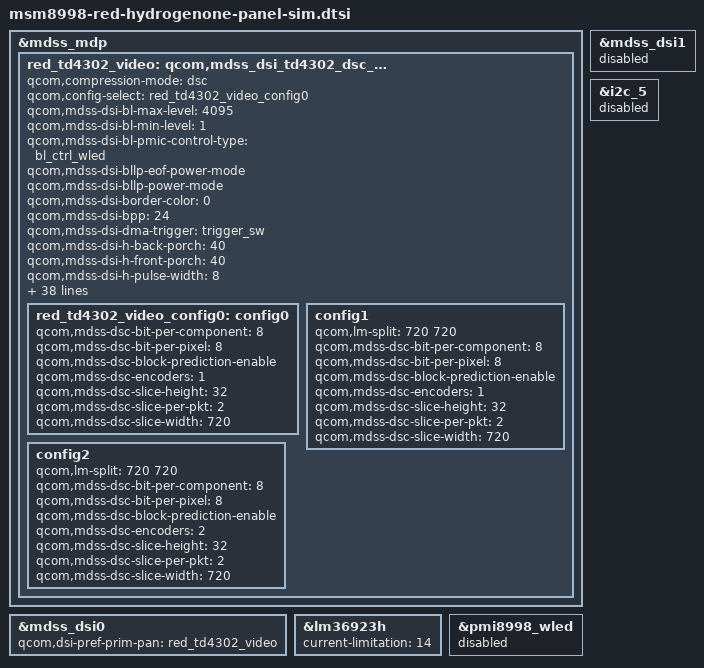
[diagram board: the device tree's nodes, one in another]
/*
 * Copyright (c) 2026, The LineageOS Project. All rights reserved.
 *
 * This program is free software; you can redistribute it and/or modify
 * it under the terms of the GNU General Public License version 2 and
 * only version 2 as published by the Free Software Foundation.
 */

/* SIM display and touch properties are isolated in this layer. */

&mdss_mdp {
	red_td4302_video: qcom,mdss_dsi_td4302_dsc_wqhd_video {
		qcom,compression-mode = "dsc";
		qcom,config-select = <&red_td4302_video_config0>;
		qcom,mdss-dsi-bl-max-level = <4095>;
		qcom,mdss-dsi-bl-min-level = <1>;
		qcom,mdss-dsi-bl-pmic-control-type = "bl_ctrl_wled";
		qcom,mdss-dsi-bllp-eof-power-mode;
		qcom,mdss-dsi-bllp-power-mode;
		qcom,mdss-dsi-border-color = <0>;
		qcom,mdss-dsi-bpp = <24>;
		qcom,mdss-dsi-dma-trigger = "trigger_sw";
		qcom,mdss-dsi-h-back-porch = <40>;
		qcom,mdss-dsi-h-front-porch = <40>;
		qcom,mdss-dsi-h-pulse-width = <8>;
		qcom,mdss-dsi-h-sync-pulse = <0>;
		qcom,mdss-dsi-h-sync-skew = <0>;
		qcom,mdss-dsi-lane-0-state;
		qcom,mdss-dsi-lane-1-state;
		qcom,mdss-dsi-lane-2-state;
		qcom,mdss-dsi-lane-3-state;
		qcom,mdss-dsi-mdp-trigger = "none";
		qcom,mdss-dsi-off-command =
			[05 01 00 00 0a 00 02 28 00
			 05 01 00 00 0a 00 02 10 00];
		qcom,mdss-dsi-off-command-state = "dsi_hs_mode";
		qcom,mdss-dsi-on-command =
			<0x05010000 0xc8000111 0x23010000 0x000002b0
			 0x04290100 0x00000004 0xb3010006 0x23010000
			 0x000002d6 0x01150100 0x00000002 0x51ff1501
			 0x00000000 0x02530c15 0x01000000 0x00025500
			 0x29010000 0x640003cf 0x48102901 0x00006400
			 0x06b632cb 0x01ffff29 0x01000064 0x0002be00
			 0x29010000 0x000002e7 0x80290100 0x00000003
			 0xeb8b8b29 0x01000064 0x0002ec01 0x05010000
			 0xa0000129>;
		qcom,mdss-dsi-on-command-state = "dsi_lp_mode";
		qcom,mdss-dsi-panel-blackness-level = <3000>;
		qcom,mdss-dsi-panel-framerate = <60>;
		qcom,mdss-dsi-panel-height = <2560>;
		qcom,mdss-dsi-panel-name = "TD4302 video mode dsc dsi panel";
		qcom,mdss-dsi-panel-peak-brightness = <4500000>;
		qcom,mdss-dsi-panel-timings = <0x00130504 0x1f1e0505 0x03030400>;
		qcom,mdss-dsi-panel-type = "dsi_video_mode";
		qcom,mdss-dsi-panel-width = <1440>;
		qcom,mdss-dsi-reset-sequence = <1 10 0 10 1 10>;
		qcom,mdss-dsi-stream = <0>;
		qcom,mdss-dsi-t-clk-post = <0x0b>;
		qcom,mdss-dsi-t-clk-pre = <0x24>;
		qcom,mdss-dsi-traffic-mode = "non_burst_sync_event";
		qcom,mdss-dsi-underflow-color = <0xff>;
		qcom,mdss-dsi-v-back-porch = <7>;
		qcom,mdss-dsi-v-front-porch = <8>;
		qcom,mdss-dsi-v-pulse-width = <1>;
		qcom,mdss-dsi-virtual-channel-id = <0>;
		qcom,mdss-pan-physical-height-dimension = <126>;
		qcom,mdss-pan-physical-width-dimension = <71>;
		qcom,panel-supply-entries = <&dsi_panel_pwr_supply>;

		red_td4302_video_config0: config0 {
			qcom,mdss-dsc-bit-per-component = <8>;
			qcom,mdss-dsc-bit-per-pixel = <8>;
			qcom,mdss-dsc-block-prediction-enable;
			qcom,mdss-dsc-encoders = <1>;
			qcom,mdss-dsc-slice-height = <32>;
			qcom,mdss-dsc-slice-per-pkt = <2>;
			qcom,mdss-dsc-slice-width = <720>;
		};

		config1 {
			qcom,lm-split = <720 720>;
			qcom,mdss-dsc-bit-per-component = <8>;
			qcom,mdss-dsc-bit-per-pixel = <8>;
			qcom,mdss-dsc-block-prediction-enable;
			qcom,mdss-dsc-encoders = <1>;
			qcom,mdss-dsc-slice-height = <32>;
			qcom,mdss-dsc-slice-per-pkt = <2>;
			qcom,mdss-dsc-slice-width = <720>;
		};

		config2 {
			qcom,lm-split = <720 720>;
			qcom,mdss-dsc-bit-per-component = <8>;
			qcom,mdss-dsc-bit-per-pixel = <8>;
			qcom,mdss-dsc-block-prediction-enable;
			qcom,mdss-dsc-encoders = <2>;
			qcom,mdss-dsc-slice-height = <32>;
			qcom,mdss-dsc-slice-per-pkt = <2>;
			qcom,mdss-dsc-slice-width = <720>;
		};
	};
};

&mdss_dsi0 {
	qcom,dsi-pref-prim-pan = <&red_td4302_video>;
	/delete-property/ qcom,panel-mode-gpio;
	/delete-property/ qcom,platform-te-gpio;
};

&mdss_dsi1 {
	status = "disabled";
};

&i2c_5 {
	status = "disabled";
};

&lm36923h {
	current-limitation = <14>;
};

&pmi8998_wled {
	status = "disabled";
};
